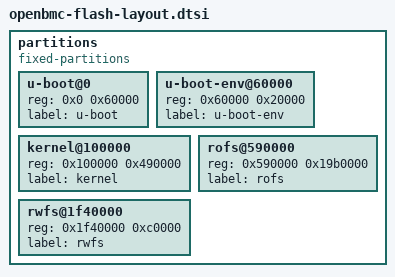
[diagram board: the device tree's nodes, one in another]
// SPDX-License-Identifier: GPL-2.0+

partitions {
	compatible = "fixed-partitions";
	#address-cells = <1>;
	#size-cells = <1>;

	u-boot@0 {
		reg = <0x0 0x60000>;
		label = "u-boot";
	};

	u-boot-env@60000 {
		reg = <0x60000 0x20000>;
		label = "u-boot-env";
	};

	kernel@100000 {
		reg = <0x100000 0x490000>;
		label = "kernel";
	};

	rofs@590000 {
		reg = <0x590000 0x19b0000>;
		label = "rofs";
	};

	rwfs@1f40000 {
		reg = <0x1f40000 0xc0000>;
		label = "rwfs";
	};
};
